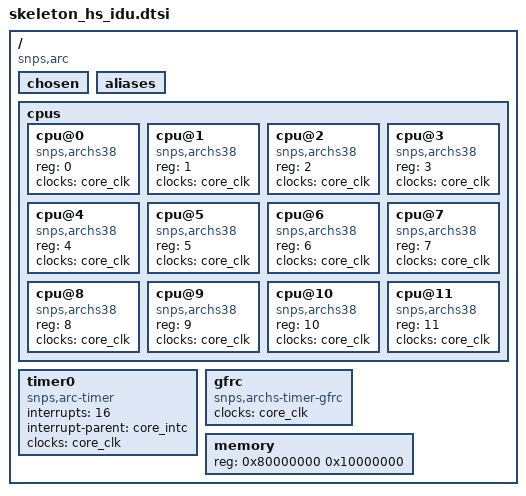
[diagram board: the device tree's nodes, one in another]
// SPDX-License-Identifier: GPL-2.0-only
/*
 * Copyright (C) 2016 Synopsys, Inc. (www.synopsys.com)
 */

/ {
	compatible = "snps,arc";
	#address-cells = <1>;
	#size-cells = <1>;
	chosen { };
	aliases { };

	cpus {
		#address-cells = <1>;
		#size-cells = <0>;

		cpu@0 {
			device_type = "cpu";
			compatible = "snps,archs38";
			reg = <0>;
			clocks = <&core_clk>;
		};
		cpu@1 {
			device_type = "cpu";
			compatible = "snps,archs38";
			reg = <1>;
			clocks = <&core_clk>;
		};
		cpu@2 {
			device_type = "cpu";
			compatible = "snps,archs38";
			reg = <2>;
			clocks = <&core_clk>;
		};
		cpu@3 {
			device_type = "cpu";
			compatible = "snps,archs38";
			reg = <3>;
			clocks = <&core_clk>;
		};
		cpu@4 {
			device_type = "cpu";
			compatible = "snps,archs38";
			reg = <4>;
			clocks = <&core_clk>;
		};
		cpu@5 {
			device_type = "cpu";
			compatible = "snps,archs38";
			reg = <5>;
			clocks = <&core_clk>;
		};
		cpu@6 {
			device_type = "cpu";
			compatible = "snps,archs38";
			reg = <6>;
			clocks = <&core_clk>;
		};
		cpu@7 {
			device_type = "cpu";
			compatible = "snps,archs38";
			reg = <7>;
			clocks = <&core_clk>;
		};
		cpu@8 {
			device_type = "cpu";
			compatible = "snps,archs38";
			reg = <8>;
			clocks = <&core_clk>;
		};
		cpu@9 {
			device_type = "cpu";
			compatible = "snps,archs38";
			reg = <9>;
			clocks = <&core_clk>;
		};
		cpu@10 {
			device_type = "cpu";
			compatible = "snps,archs38";
			reg = <10>;
			clocks = <&core_clk>;
		};
		cpu@11 {
			device_type = "cpu";
			compatible = "snps,archs38";
			reg = <11>;
			clocks = <&core_clk>;
		};
	};

	/* TIMER0 with interrupt for clockevent */
	timer0 {
		compatible = "snps,arc-timer";
		interrupts = <16>;
		interrupt-parent = <&core_intc>;
		clocks = <&core_clk>;
	};

	/* 64-bit Global Free Running Counter */
	gfrc {
		compatible = "snps,archs-timer-gfrc";
		clocks = <&core_clk>;
	};

	memory {
		device_type = "memory";
		reg = <0x80000000 0x10000000>;	/* 256M */
	};
};
